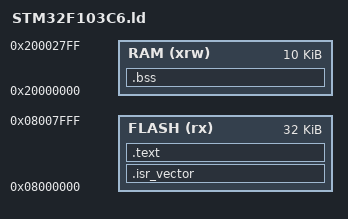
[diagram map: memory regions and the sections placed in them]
ENTRY(Reset_Handler)

_estack = 0x20002800; /* End of 10K RAM */

MEMORY
{
  FLASH (rx) : ORIGIN = 0x08000000, LENGTH = 32K
  RAM (xrw)  : ORIGIN = 0x20000000, LENGTH = 10K
}

SECTIONS
{
  .isr_vector :
  {
    . = ALIGN(4);
    KEEP(*(.isr_vector))
    . = ALIGN(4);
  } >FLASH

  .text :
  {
    . = ALIGN(4);
    *(.text)
    *(.text*)
    . = ALIGN(4);
  } >FLASH

  .bss :
  {
    . = ALIGN(4);
    _sbss = .;
    *(.bss)
    *(COMMON)
    . = ALIGN(4);
    _ebss = .;
  } >RAM
}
